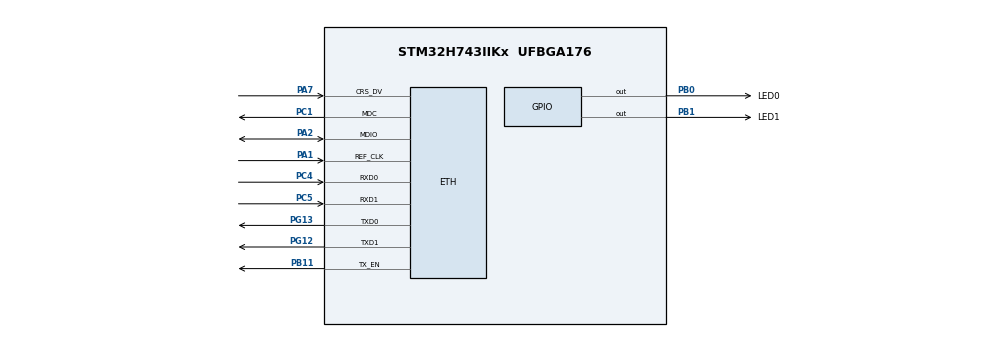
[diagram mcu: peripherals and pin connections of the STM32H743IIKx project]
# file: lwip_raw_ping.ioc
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CORTEX_M7.AccessPermission-Cortex_Memory_Protection_Unit_Region0_Settings=MPU_REGION_FULL_ACCESS
CORTEX_M7.AccessPermission-Cortex_Memory_Protection_Unit_Region1_Settings=MPU_REGION_FULL_ACCESS
CORTEX_M7.BaseAddress-Cortex_Memory_Protection_Unit_Region0_Settings=0x30040000
CORTEX_M7.BaseAddress-Cortex_Memory_Protection_Unit_Region1_Settings=0x30044000
CORTEX_M7.CPU_DCache=Enabled
CORTEX_M7.CPU_ICache=Enabled
CORTEX_M7.Enable-Cortex_Memory_Protection_Unit_Region0_Settings=MPU_REGION_ENABLE
CORTEX_M7.Enable-Cortex_Memory_Protection_Unit_Region1_Settings=MPU_REGION_ENABLE
CORTEX_M7.IsBufferable-Cortex_Memory_Protection_Unit_Region0_Settings=MPU_ACCESS_BUFFERABLE
CORTEX_M7.IsCacheable-Cortex_Memory_Protection_Unit_Region1_Settings=MPU_ACCESS_CACHEABLE
CORTEX_M7.MPU_Control=MPU_PRIVILEGED_DEFAULT
CORTEX_M7.Size-Cortex_Memory_Protection_Unit_Region0_Settings=MPU_REGION_SIZE_256B
CORTEX_M7.Size-Cortex_Memory_Protection_Unit_Region1_Settings=MPU_REGION_SIZE_16KB
ETH.MediaInterface=HAL_ETH_RMII_MODE
ETH.RxBuffLen=1528
FREERTOS.Tasks01=defaultTask,0,512,StartDefaultTask,Default,NULL,Dynamic,NULL,NULL
FREERTOS.configMAX_PRIORITIES=32
LWIP.BSP.number=1
LWIP.DEFAULT_THREAD_PRIO=3
LWIP.GATEWAY_ADDRESS=192.168.001.000
LWIP.IP_ADDRESS=192.168.101.140
LWIP.LWIP_DHCP=0
LWIP.LWIP_NETIF_LINK_CALLBACK=1
LWIP.MEM_SIZE=10240
LWIP.NETMASK_ADDRESS=255.255.255.000
LWIP.PBUF_POOL_BUFSIZE=1528
LWIP.TCPIP_THREAD_PRIO=3
LWIP.TCP_MSS=1460
LWIP.TCP_WND=5840
LWIP.Version=v2.0.3_Cube
LWIP0.BSP.STBoard=false
LWIP0.BSP.api=BSP_COMPONENT_DRIVER
LWIP0.BSP.component=LAN8742
LWIP0.BSP.i2caddr=0
LWIP0.BSP.instance=LAN8742
LWIP0.BSP.name=Driver_PHY
LWIP0.BSP.solution=LAN8742
Mcu.Family=STM32H7
Mcu.Name=STM32H743IIKx
Mcu.Package=UFBGA176
NVIC.ETH_IRQn=true\:7\:0\:true\:false\:true\:true\:true\:true
NVIC.PriorityGroup=NVIC_PRIORITYGROUP_4
PA1.GPIO_Speed=GPIO_SPEED_FREQ_VERY_HIGH
PA1.Mode=RMII
PA1.Signal=ETH_REF_CLK
PA13\ (JTMS/SWDIO).Mode=Trace_Asynchronous_SW
PA13\ (JTMS/SWDIO).Signal=DEBUG_JTMS-SWDIO
PA14\ (JTCK/SWCLK).Mode=Trace_Asynchronous_SW
PA14\ (JTCK/SWCLK).Signal=DEBUG_JTCK-SWCLK
PA2.GPIO_Speed=GPIO_SPEED_FREQ_VERY_HIGH
PA2.Mode=RMII
PA2.Signal=ETH_MDIO
PA7.GPIO_Speed=GPIO_SPEED_FREQ_VERY_HIGH
PA7.Mode=RMII
PA7.Signal=ETH_CRS_DV
PB0.GPIO_Label=LED0
PB0.PinState=GPIO_PIN_SET
PB0.Signal=GPIO_Output
PB1.GPIO_Label=LED1
PB1.PinState=GPIO_PIN_SET
PB1.Signal=GPIO_Output
PB11.GPIO_Speed=GPIO_SPEED_FREQ_VERY_HIGH
PB11.Mode=RMII
PB11.Signal=ETH_TX_EN
PB3\ (JTDO/TRACESWO).Mode=Trace_Asynchronous_SW
PB3\ (JTDO/TRACESWO).Signal=DEBUG_JTDO-SWO
PC1.Mode=RMII
PC1.Signal=ETH_MDC
PC4.GPIO_Speed=GPIO_SPEED_FREQ_VERY_HIGH
PC4.Mode=RMII
PC4.Signal=ETH_RXD0
PC5.GPIO_Speed=GPIO_SPEED_FREQ_VERY_HIGH
PC5.Mode=RMII
PC5.Signal=ETH_RXD1
PG12.GPIO_Speed=GPIO_SPEED_FREQ_VERY_HIGH
PG12.Mode=RMII
PG12.Signal=ETH_TXD1
PG13.GPIO_Speed=GPIO_SPEED_FREQ_VERY_HIGH
PG13.Mode=RMII
PG13.Signal=ETH_TXD0
PH0-OSC_IN\ (PH0).Mode=HSE-External-Oscillator
PH0-OSC_IN\ (PH0).Signal=RCC_OSC_IN
PH1-OSC_OUT\ (PH1).Mode=HSE-External-Oscillator
PH1-OSC_OUT\ (PH1).Signal=RCC_OSC_OUT
ProjectManager.HeapSize=0x4000
ProjectManager.StackSize=0x8000
ProjectManager.TargetToolchain=STM32CubeIDE
RCC.ADCFreq_Value=50390625
RCC.APB1Freq_Value=100000000
RCC.APB2Freq_Value=100000000
RCC.APB3Freq_Value=100000000
RCC.APB4Freq_Value=100000000
RCC.CortexFreq_Value=400000000
RCC.D1PPRE=RCC_APB3_DIV2
RCC.D2PPRE1=RCC_APB1_DIV2
RCC.D2PPRE2=RCC_APB2_DIV2
RCC.D3PPRE=RCC_APB4_DIV2
RCC.DIVM1=2
RCC.DIVN1=64
RCC.HCLKFreq_Value=200000000
RCC.HPRE=RCC_HCLK_DIV2
RCC.PLL2FRACN=0
RCC.PLL3FRACN=0
RCC.PLLFRACN=0
RCC.PLLSourceVirtual=RCC_PLLSOURCE_HSE
RCC.SYSCLKFreq_VALUE=400000000
RCC.SYSCLKSource=RCC_SYSCLKSOURCE_PLLCLK
RCC.USBFreq_Value=400000000
VP_FREERTOS_VS_CMSIS_V1.Mode=CMSIS_V1
VP_LWIP_VS_Enabled.Mode=Enabled
board=custom

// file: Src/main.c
/* USER CODE BEGIN Header */
/**
  ******************************************************************************
  * @file           : main.c
  * @brief          : Main program body
  ******************************************************************************
  * @attention
  *
  * <h2><center>&copy; Copyright (c) 2020 STMicroelectronics.
  * All rights reserved.</center></h2>
  *
  * This software component is licensed by ST under Ultimate Liberty license
  * SLA0044, the "License"; You may not use this file except in compliance with
  * the License. You may obtain a copy of the License at:
  *                             www.st.com/SLA0044
  *
  ******************************************************************************
  */
/* USER CODE END Header */

#include "main.h"
#include "cmsis_os.h"
#include "lwip.h"
#include "gpio.h"

void SystemClock_Config(void);
static void MPU_Config(void);
void MX_FREERTOS_Init(void);

int main(void)
{

  /* MPU Configuration--------------------------------------------------------*/
  MPU_Config();

  /* Enable I-Cache---------------------------------------------------------*/
  SCB_EnableICache();

  /* Enable D-Cache---------------------------------------------------------*/
  SCB_EnableDCache();

  /* MCU Configuration--------------------------------------------------------*/

  /* Reset of all peripherals, Initializes the Flash interface and the Systick. */
  HAL_Init();

  /* Configure the system clock */
  SystemClock_Config();

  /* Initialize all configured peripherals */
  MX_GPIO_Init();

  /* Call init function for freertos objects (in freertos.c) */
  MX_FREERTOS_Init();

  /* Start scheduler */
  osKernelStart();

  /* We should never get here as control is now taken by the scheduler */

  /* Infinite loop */
  while (1)
  {

  }
}

void SystemClock_Config(void)
{
  RCC_OscInitTypeDef RCC_OscInitStruct = {0};
  RCC_ClkInitTypeDef RCC_ClkInitStruct = {0};

  /** Supply configuration update enable
  */
  HAL_PWREx_ConfigSupply(PWR_LDO_SUPPLY);
  /** Configure the main internal regulator output voltage
  */
  __HAL_PWR_VOLTAGESCALING_CONFIG(PWR_REGULATOR_VOLTAGE_SCALE1);

  while(!__HAL_PWR_GET_FLAG(PWR_FLAG_VOSRDY)) {}

  /* Enable D2 domain SRAM3 Clock (0x30040000 AXI)*/
  __HAL_RCC_D2SRAM3_CLK_ENABLE();
/** Initializes the CPU, AHB and APB busses clocks
 *
*/
  RCC_OscInitStruct.OscillatorType = RCC_OSCILLATORTYPE_HSE;
  RCC_OscInitStruct.HSEState = RCC_HSE_ON;
  RCC_OscInitStruct.PLL.PLLState = RCC_PLL_ON;
  RCC_OscInitStruct.PLL.PLLSource = RCC_PLLSOURCE_HSE;
  RCC_OscInitStruct.PLL.PLLM = 2;
  RCC_OscInitStruct.PLL.PLLN = 64;
  RCC_OscInitStruct.PLL.PLLP = 2;
  RCC_OscInitStruct.PLL.PLLQ = 2;
  RCC_OscInitStruct.PLL.PLLR = 2;
  RCC_OscInitStruct.PLL.PLLRGE = RCC_PLL1VCIRANGE_3;
  RCC_OscInitStruct.PLL.PLLVCOSEL = RCC_PLL1VCOWIDE;
  RCC_OscInitStruct.PLL.PLLFRACN = 0;
  if (HAL_RCC_OscConfig(&RCC_OscInitStruct) != HAL_OK)
  {
    Error_Handler();
  }
  /** Initializes the CPU, AHB and APB busses clocks
  */
  RCC_ClkInitStruct.ClockType = RCC_CLOCKTYPE_HCLK|RCC_CLOCKTYPE_SYSCLK
                              |RCC_CLOCKTYPE_PCLK1|RCC_CLOCKTYPE_PCLK2
                              |RCC_CLOCKTYPE_D3PCLK1|RCC_CLOCKTYPE_D1PCLK1;
  RCC_ClkInitStruct.SYSCLKSource = RCC_SYSCLKSOURCE_PLLCLK;
  RCC_ClkInitStruct.SYSCLKDivider = RCC_SYSCLK_DIV1;
  RCC_ClkInitStruct.AHBCLKDivider = RCC_HCLK_DIV2;
  RCC_ClkInitStruct.APB3CLKDivider = RCC_APB3_DIV2;
  RCC_ClkInitStruct.APB1CLKDivider = RCC_APB1_DIV2;
  RCC_ClkInitStruct.APB2CLKDivider = RCC_APB2_DIV2;
  RCC_ClkInitStruct.APB4CLKDivider = RCC_APB4_DIV2;

  if (HAL_RCC_ClockConfig(&RCC_ClkInitStruct, FLASH_LATENCY_2) != HAL_OK)
  {
    Error_Handler();
  }
}

/* MPU Configuration */

void MPU_Config(void)
{
  MPU_Region_InitTypeDef MPU_InitStruct = {0};

  /* Disables the MPU */
  HAL_MPU_Disable();
  /** Initializes and configures the Region and the memory to be protected
  */
  MPU_InitStruct.Enable = MPU_REGION_ENABLE;
  MPU_InitStruct.Number = MPU_REGION_NUMBER0;
  MPU_InitStruct.BaseAddress = 0x30040000;
  MPU_InitStruct.Size = MPU_REGION_SIZE_256B;
  MPU_InitStruct.SubRegionDisable = 0x0;
  MPU_InitStruct.TypeExtField = MPU_TEX_LEVEL0;
  MPU_InitStruct.AccessPermission = MPU_REGION_FULL_ACCESS;
  MPU_InitStruct.DisableExec = MPU_INSTRUCTION_ACCESS_ENABLE;
  MPU_InitStruct.IsShareable = MPU_ACCESS_NOT_SHAREABLE;
  MPU_InitStruct.IsCacheable = MPU_ACCESS_NOT_CACHEABLE;
  MPU_InitStruct.IsBufferable = MPU_ACCESS_BUFFERABLE;

  HAL_MPU_ConfigRegion(&MPU_InitStruct);
  /** Initializes and configures the Region and the memory to be protected
  */
  MPU_InitStruct.Enable = MPU_REGION_ENABLE;
  MPU_InitStruct.Number = MPU_REGION_NUMBER1;
  MPU_InitStruct.BaseAddress = 0x30044000;
  MPU_InitStruct.Size = MPU_REGION_SIZE_16KB;
  MPU_InitStruct.SubRegionDisable = 0x0;
  MPU_InitStruct.TypeExtField = MPU_TEX_LEVEL0;
  MPU_InitStruct.AccessPermission = MPU_REGION_FULL_ACCESS;
  MPU_InitStruct.DisableExec = MPU_INSTRUCTION_ACCESS_ENABLE;
  MPU_InitStruct.IsShareable = MPU_ACCESS_NOT_SHAREABLE;
  MPU_InitStruct.IsCacheable = MPU_ACCESS_CACHEABLE;
  MPU_InitStruct.IsBufferable = MPU_ACCESS_NOT_BUFFERABLE;

  HAL_MPU_ConfigRegion(&MPU_InitStruct);
  /* Enables the MPU */
  HAL_MPU_Enable(MPU_PRIVILEGED_DEFAULT);

}

void Error_Handler(void)
{
}

/************************ (C) COPYRIGHT STMicroelectronics *****END OF FILE****/

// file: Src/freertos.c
/* USER CODE BEGIN Header */
/**
  ******************************************************************************
  * File Name          : freertos.c
  * Description        : Code for freertos applications
  ******************************************************************************
  * @attention
  *
  * <h2><center>&copy; Copyright (c) 2020 STMicroelectronics.
  * All rights reserved.</center></h2>
  *
  * This software component is licensed by ST under Ultimate Liberty license
  * SLA0044, the "License"; You may not use this file except in compliance with
  * the License. You may obtain a copy of the License at:
  *                             www.st.com/SLA0044
  *
  ******************************************************************************
  */
/* USER CODE END Header */

#include <tcpecho_netconn.h>
#include <udpecho_netconn.h>
#include "FreeRTOS.h"
#include "task.h"
#include "main.h"
#include "cmsis_os.h"

/* USER CODE BEGIN Includes */
#include "client_netconn.h"
#include "client_socket.h"
#include "iperf_socket_client.h"
/* USER CODE END Includes */

/* USER CODE BEGIN PTD */
osThreadId led1TaskHandle;
osThreadId led2TaskHandle;

static void led1BlinkTask(void* parameter);
static void led2BlinkTask(void* parameter);
/* USER CODE END PTD */

osThreadId defaultTaskHandle;

void StartDefaultTask(void const * argument);

extern void MX_LWIP_Init(void);
void MX_FREERTOS_Init(void); /* (MISRA C 2004 rule 8.1) */

void MX_FREERTOS_Init(void) {

  /* Create the thread(s) */
  /* definition and creation of defaultTask */
  osThreadDef(defaultTask, StartDefaultTask, osPriorityNormal, 0, 512);
  defaultTaskHandle = osThreadCreate(osThread(defaultTask), NULL);

//  osThreadDef(led1Task, led1BlinkTask, osPriorityNormal, 0, 128);
//  led1TaskHandle = osThreadCreate(osThread(led1Task), NULL);
//
//  osThreadDef(led2Task, led2BlinkTask, osPriorityNormal, 0, 128);
//  led2TaskHandle = osThreadCreate(osThread(led2Task), NULL);

}

void StartDefaultTask(void const * argument)
{

  /* init code for LWIP */
  MX_LWIP_Init();

//  client_netconn_init();
//  tcpecho_init();
//  udpecho_init();
//  client_socket_init();
//  iperf_server_init();
  iperf_socket_client_init();

//  vPortEnterCritical();
//
//
//
//  vTaskDelete(defaultTaskHandle);
//
//  vPortExitCritical();

  for(;;)
  {
    osDelay(1);
  }
}

/* USER CODE BEGIN Application */
static void led1BlinkTask(void* parameter){
	while(1){
		HAL_GPIO_TogglePin(LED0_GPIO_Port, LED0_Pin);
		osDelay(500);
	}
}

static void led2BlinkTask(void* parameter){
	while(1){
		HAL_GPIO_TogglePin(LED1_GPIO_Port, LED1_Pin);
		osDelay(1000);
	}
}
/* USER CODE END Application */

/************************ (C) COPYRIGHT STMicroelectronics *****END OF FILE****/
